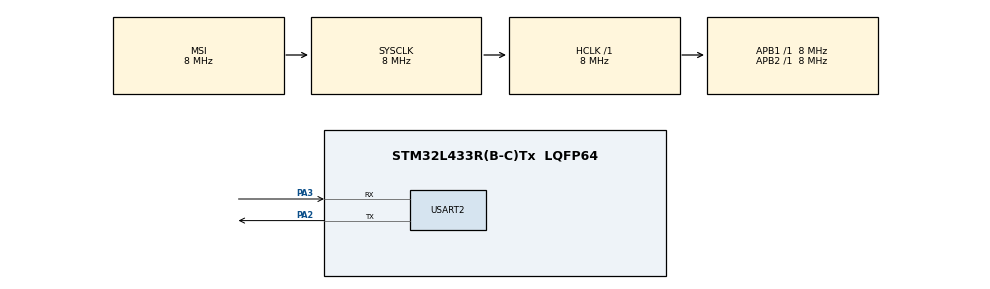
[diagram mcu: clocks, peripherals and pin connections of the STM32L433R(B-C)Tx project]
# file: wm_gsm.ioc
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Mcu.Family=STM32L4
Mcu.Name=STM32L433R(B-C)Tx
Mcu.Package=LQFP64
NVIC.PriorityGroup=NVIC_PRIORITYGROUP_4
PA13\ (JTMS-SWDIO).Mode=Serial_Wire
PA13\ (JTMS-SWDIO).Signal=SYS_JTMS-SWDIO
PA14\ (JTCK-SWCLK).Mode=Serial_Wire
PA14\ (JTCK-SWCLK).Signal=SYS_JTCK-SWCLK
PA2.Mode=Asynchronous
PA2.Signal=USART2_TX
PA3.Mode=Asynchronous
PA3.Signal=USART2_RX
ProjectManager.HeapSize=0x400
ProjectManager.StackSize=0x800
ProjectManager.TargetToolchain=EWARM V8.32
RCC.ADCCLockSelection=RCC_ADCCLKSOURCE_SYSCLK
RCC.ADCFreq_Value=8000000
RCC.AHBFreq_Value=8000000
RCC.APB1Freq_Value=8000000
RCC.APB1TimFreq_Value=8000000
RCC.APB2Freq_Value=8000000
RCC.APB2TimFreq_Value=8000000
RCC.CortexFreq_Value=8000000
RCC.HCLKFreq_Value=8000000
RCC.HSE_VALUE=8000000
RCC.HSI48_VALUE=48000000
RCC.HSI_VALUE=16000000
RCC.LPTIM1CLockSelection=RCC_LPTIM1CLKSOURCE_LSE
RCC.MSIClockRange=RCC_MSIRANGE_7
RCC.MSI_VALUE=8000000
RCC.PLLSAI1N=16
RCC.RTCClockSelection=RCC_RTCCLKSOURCE_LSE
RCC.SYSCLKFreq_VALUE=8000000
RCC.USBFreq_Value=64000000
RCC.VCOOutputFreq_Value=64000000
USART2.VirtualMode-Asynchronous=VM_ASYNC
board=custom

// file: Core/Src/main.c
/* USER CODE BEGIN Header */
/**
  ******************************************************************************
  * @file           : main.c
  * @brief          : Main program body
  ******************************************************************************
  * @attention
  *
  * Copyright (c) 2024 STMicroelectronics.
  * All rights reserved.
  *
  * This software is licensed under terms that can be found in the LICENSE file
  * in the root directory of this software component.
  * If no LICENSE file comes with this software, it is provided AS-IS.
  *
  ******************************************************************************
  */
/* USER CODE END Header */
#include "main.h"
#include "usart.h"
#include "gpio.h"

/* USER CODE BEGIN Includes */
#include "onchipflash.h"
#include "user_internal_mem.h"
#include "user_util.h"
/* USER CODE END Includes */

/* USER CODE BEGIN PV */
uint32_t	HaveNewFirmware = 0;
uint32_t	NewFirmwareSize = 0;
uint32_t	JumpAddress;
uint32_t	i = 0;

typedef  void (*pFunction)(void);
pFunction Jump_To_Application;
/* USER CODE END PV */

void SystemClock_Config(void);

/* USER CODE BEGIN 0 */
static void AppComm_Uart_Debug_Send (uint8_t *pData, uint16_t Length)
{
    HAL_UART_Transmit(&huart2, pData, Length, 1000);
}

/* USER CODE END 0 */

int main(void)
{

  /* MCU Configuration--------------------------------------------------------*/

  /* Reset of all peripherals, Initializes the Flash interface and the Systick. */
  HAL_Init();

  /* Configure the system clock */
  SystemClock_Config();

  /* Initialize all configured peripherals */
//  MX_GPIO_Init();
  MX_USART2_UART_Init();
  /* USER CODE BEGIN 2 */
  pFunc_UTIL_Debug_Send  = &AppComm_Uart_Debug_Send;

    UTIL_Printf_Str (DBLEVEL_L, "\r\n=====BOOT LOADER V4====\r\n");

    HaveNewFirmware = *(__IO uint32_t*)(ADDR_FLAG_HAVE_NEW_FW);
	NewFirmwareSize = *(__IO uint32_t*)(ADDR_FLAG_HAVE_NEW_FW + FLASH_BYTE_WRTIE);

	if (HaveNewFirmware == 0xAA)
	{
        UTIL_Printf_Str (_VLEVEL_DEBUG, "u_main: find new image\r\n");

        UTIL_Printf_Str (_VLEVEL_DEBUG, "u_main: erase main image\r\n");
        Erase_Firmware (ADDR_MAIN_PROGRAM, FIRMWARE_SIZE_PAGE);

		// Copy new firmware to right position
        UTIL_Printf_Str (_VLEVEL_DEBUG, "u_main: copy new image to main\r\n");
		OnchipFlashCopy(ADDR_UPDATE_PROGRAM, ADDR_MAIN_PROGRAM, NewFirmwareSize);

		//Clear new firmware flag
        UTIL_Printf_Str (_VLEVEL_DEBUG, "u_main: erase mark new image\r\n");
		OnchipFlashPageErase(ADDR_FLAG_HAVE_NEW_FW);
	}

    /*  them 21_04 */
	HAL_RCC_DeInit();
	HAL_DeInit();
	SCB->SHCSR &= ~( SCB_SHCSR_USGFAULTENA_Msk |\
					SCB_SHCSR_BUSFAULTENA_Msk |\
					SCB_SHCSR_MEMFAULTENA_Msk );

//	__disable_irq();

	JumpAddress = *((__IO uint32_t*)(ADDR_MAIN_PROGRAM + 0x04));

	Jump_To_Application = (pFunction) JumpAddress;

	// Initialize user application's Stack Pointer
	__set_MSP(*(__IO uint32_t*) ADDR_MAIN_PROGRAM);

	Jump_To_Application();
  /* USER CODE END 2 */

  /* Infinite loop */
  while (1)
  {

  }
}

void SystemClock_Config(void)
{
  RCC_OscInitTypeDef RCC_OscInitStruct = {0};
  RCC_ClkInitTypeDef RCC_ClkInitStruct = {0};

  /** Configure the main internal regulator output voltage
  */
  if (HAL_PWREx_ControlVoltageScaling(PWR_REGULATOR_VOLTAGE_SCALE1) != HAL_OK)
  {
    Error_Handler();
  }

  /** Initializes the RCC Oscillators according to the specified parameters
  * in the RCC_OscInitTypeDef structure.
  */
  RCC_OscInitStruct.OscillatorType = RCC_OSCILLATORTYPE_MSI;
  RCC_OscInitStruct.MSIState = RCC_MSI_ON;
  RCC_OscInitStruct.MSICalibrationValue = 0;
  RCC_OscInitStruct.MSIClockRange = RCC_MSIRANGE_7;
  RCC_OscInitStruct.PLL.PLLState = RCC_PLL_NONE;
  if (HAL_RCC_OscConfig(&RCC_OscInitStruct) != HAL_OK)
  {
    Error_Handler();
  }

  /** Initializes the CPU, AHB and APB buses clocks
  */
  RCC_ClkInitStruct.ClockType = RCC_CLOCKTYPE_HCLK|RCC_CLOCKTYPE_SYSCLK
                              |RCC_CLOCKTYPE_PCLK1|RCC_CLOCKTYPE_PCLK2;
  RCC_ClkInitStruct.SYSCLKSource = RCC_SYSCLKSOURCE_MSI;
  RCC_ClkInitStruct.AHBCLKDivider = RCC_SYSCLK_DIV1;
  RCC_ClkInitStruct.APB1CLKDivider = RCC_HCLK_DIV1;
  RCC_ClkInitStruct.APB2CLKDivider = RCC_HCLK_DIV1;

  if (HAL_RCC_ClockConfig(&RCC_ClkInitStruct, FLASH_LATENCY_0) != HAL_OK)
  {
    Error_Handler();
  }
}

void Error_Handler(void)
{
  __disable_irq();
  while (1)
  {
  }
}
